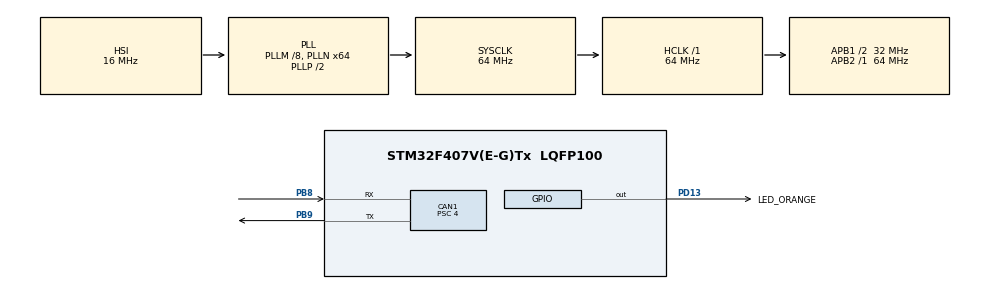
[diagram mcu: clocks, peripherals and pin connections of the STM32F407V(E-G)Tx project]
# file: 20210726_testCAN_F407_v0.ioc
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CAN1.ABOM=ENABLE
CAN1.BS1=CAN_BS1_13TQ
CAN1.BS2=CAN_BS2_2TQ
CAN1.CalculateTimeQuantum=125.0
CAN1.NART=ENABLE
CAN1.Prescaler=4
CAN1.TXFP=ENABLE
Mcu.Family=STM32F4
Mcu.Name=STM32F407V(E-G)Tx
Mcu.Package=LQFP100
NVIC.CAN1_RX0_IRQn=true\:0\:0\:false\:false\:true\:true\:true
NVIC.CAN1_SCE_IRQn=true\:0\:0\:false\:false\:true\:true\:true
NVIC.PriorityGroup=NVIC_PRIORITYGROUP_4
PA13.Mode=Serial_Wire
PA13.Signal=SYS_JTMS-SWDIO
PA14.Mode=Serial_Wire
PA14.Signal=SYS_JTCK-SWCLK
PB8.Mode=Master
PB8.Signal=CAN1_RX
PB9.Mode=Master
PB9.Signal=CAN1_TX
PD13.GPIO_Label=LED_ORANGE
PD13.Signal=GPIO_Output
PH0-OSC_IN.Mode=HSE-External-Oscillator
PH0-OSC_IN.Signal=RCC_OSC_IN
PH1-OSC_OUT.Mode=HSE-External-Oscillator
PH1-OSC_OUT.Signal=RCC_OSC_OUT
ProjectManager.HeapSize=0x200
ProjectManager.StackSize=0x400
ProjectManager.TargetToolchain=STM32CubeIDE
RCC.48MHZClocksFreq_Value=32000000
RCC.AHBFreq_Value=64000000
RCC.APB1CLKDivider=RCC_HCLK_DIV2
RCC.APB1Freq_Value=32000000
RCC.APB1TimFreq_Value=64000000
RCC.APB2Freq_Value=64000000
RCC.APB2TimFreq_Value=64000000
RCC.CortexFreq_Value=64000000
RCC.HCLKFreq_Value=64000000
RCC.HSE_VALUE=8000000
RCC.HSI_VALUE=16000000
RCC.LSE_VALUE=32768
RCC.PLLM=8
RCC.PLLN=64
RCC.SYSCLKFreq_VALUE=64000000
RCC.SYSCLKSource=RCC_SYSCLKSOURCE_PLLCLK
RCC.VCOOutputFreq_Value=128000000
board=custom

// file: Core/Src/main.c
/* USER CODE BEGIN Header */
/**
  ******************************************************************************
  * @file           : main.c
  * @brief          : Main program body
  ******************************************************************************
  * @attention
  *
  * <h2><center>&copy; Copyright (c) 2021 STMicroelectronics.
  * All rights reserved.</center></h2>
  *
  * This software component is licensed by ST under BSD 3-Clause license,
  * the "License"; You may not use this file except in compliance with the
  * License. You may obtain a copy of the License at:
  *                        opensource.org/licenses/BSD-3-Clause
  *
  ******************************************************************************
  */
/* USER CODE END Header */

#include "main.h"

CAN_HandleTypeDef hcan1;

/* USER CODE BEGIN PV */
CAN_TxHeaderTypeDef TxHeader;
CAN_RxHeaderTypeDef RxHeader;
uint8_t TxData[8] = {0,};
uint8_t RxData[8] = {0,};
uint32_t TxMailbox = 0;
/* USER CODE END PV */

void SystemClock_Config(void);
static void MX_GPIO_Init(void);
static void MX_CAN1_Init(void);

/* USER CODE BEGIN 0 */
void HAL_CAN_RxFifo0MsgPendingCallback(CAN_HandleTypeDef *hcan)
{
    if(HAL_CAN_GetRxMessage(hcan, CAN_RX_FIFO0, &RxHeader, RxData) == HAL_OK)
    {
        HAL_GPIO_TogglePin(LED_ORANGE_GPIO_Port, LED_ORANGE_Pin);
    }
}

void HAL_CAN_ErrorCallback(CAN_HandleTypeDef *hcan)
{
//    uint32_t er = HAL_CAN_GetError(hcan);
//    sprintf(trans_str,"ER CAN %lu %08lX", er, er);
//    HAL_UART_Transmit(&huart1, (uint8_t*)trans_str, strlen(trans_str), 100);
}
/* USER CODE END 0 */

int main(void)
{

  /* MCU Configuration--------------------------------------------------------*/

  /* Reset of all peripherals, Initializes the Flash interface and the Systick. */
  HAL_Init();

  /* Configure the system clock */
  SystemClock_Config();

  /* Initialize all configured peripherals */
  MX_GPIO_Init();
  MX_CAN1_Init();
  /* USER CODE BEGIN 2 */
  TxHeader.StdId = 0x0378;
  TxHeader.ExtId = 0;
  TxHeader.RTR = CAN_RTR_DATA; //CAN_RTR_REMOTE
  TxHeader.IDE = CAN_ID_STD;   // CAN_ID_EXT
  TxHeader.DLC = 8;
  TxHeader.TransmitGlobalTime = 0;

  for(uint8_t i = 0; i < 8; i++)
  {
      TxData[i] = (i + 10);
  }

  HAL_CAN_Start(&hcan1);

  HAL_CAN_ActivateNotification(&hcan1, CAN_IT_RX_FIFO0_MSG_PENDING | CAN_IT_ERROR | CAN_IT_BUSOFF | CAN_IT_LAST_ERROR_CODE);
  /* USER CODE END 2 */

  /* Infinite loop */
  /* USER CODE BEGIN WHILE */
  while (1)
  {
	  while(HAL_CAN_GetTxMailboxesFreeLevel(&hcan1) == 0);

    /* USER CODE END WHILE */

  }
}

void SystemClock_Config(void)
{
  RCC_OscInitTypeDef RCC_OscInitStruct = {0};
  RCC_ClkInitTypeDef RCC_ClkInitStruct = {0};

  /** Configure the main internal regulator output voltage
  */
  __HAL_RCC_PWR_CLK_ENABLE();
  __HAL_PWR_VOLTAGESCALING_CONFIG(PWR_REGULATOR_VOLTAGE_SCALE1);
  /** Initializes the CPU, AHB and APB busses clocks
  */
  RCC_OscInitStruct.OscillatorType = RCC_OSCILLATORTYPE_HSI;
  RCC_OscInitStruct.HSIState = RCC_HSI_ON;
  RCC_OscInitStruct.HSICalibrationValue = RCC_HSICALIBRATION_DEFAULT;
  RCC_OscInitStruct.PLL.PLLState = RCC_PLL_ON;
  RCC_OscInitStruct.PLL.PLLSource = RCC_PLLSOURCE_HSI;
  RCC_OscInitStruct.PLL.PLLM = 8;
  RCC_OscInitStruct.PLL.PLLN = 64;
  RCC_OscInitStruct.PLL.PLLP = RCC_PLLP_DIV2;
  RCC_OscInitStruct.PLL.PLLQ = 4;
  if (HAL_RCC_OscConfig(&RCC_OscInitStruct) != HAL_OK)
  {
    Error_Handler();
  }
  /** Initializes the CPU, AHB and APB busses clocks
  */
  RCC_ClkInitStruct.ClockType = RCC_CLOCKTYPE_HCLK|RCC_CLOCKTYPE_SYSCLK
                              |RCC_CLOCKTYPE_PCLK1|RCC_CLOCKTYPE_PCLK2;
  RCC_ClkInitStruct.SYSCLKSource = RCC_SYSCLKSOURCE_PLLCLK;
  RCC_ClkInitStruct.AHBCLKDivider = RCC_SYSCLK_DIV1;
  RCC_ClkInitStruct.APB1CLKDivider = RCC_HCLK_DIV2;
  RCC_ClkInitStruct.APB2CLKDivider = RCC_HCLK_DIV1;

  if (HAL_RCC_ClockConfig(&RCC_ClkInitStruct, FLASH_LATENCY_2) != HAL_OK)
  {
    Error_Handler();
  }
}

static void MX_CAN1_Init(void)
{

  /* USER CODE BEGIN CAN1_Init 0 */
	CAN_FilterTypeDef  sFilterConfig;
  /* USER CODE END CAN1_Init 0 */

  hcan1.Instance = CAN1;
  hcan1.Init.Prescaler = 4;
  hcan1.Init.Mode = CAN_MODE_NORMAL;
  hcan1.Init.SyncJumpWidth = CAN_SJW_1TQ;
  hcan1.Init.TimeSeg1 = CAN_BS1_13TQ;
  hcan1.Init.TimeSeg2 = CAN_BS2_2TQ;
  hcan1.Init.TimeTriggeredMode = DISABLE;
  hcan1.Init.AutoBusOff = ENABLE;
  hcan1.Init.AutoWakeUp = DISABLE;
  hcan1.Init.AutoRetransmission = ENABLE;
  hcan1.Init.ReceiveFifoLocked = DISABLE;
  hcan1.Init.TransmitFifoPriority = ENABLE;
  if (HAL_CAN_Init(&hcan1) != HAL_OK)
  {
    Error_Handler();
  }
  /* USER CODE BEGIN CAN1_Init 2 */
  sFilterConfig.FilterBank = 0;
  sFilterConfig.FilterMode = CAN_FILTERMODE_IDMASK;
  sFilterConfig.FilterScale = CAN_FILTERSCALE_32BIT;
  sFilterConfig.FilterIdHigh = 0x0000;
  sFilterConfig.FilterIdLow = 0x0000;
  sFilterConfig.FilterMaskIdHigh = 0x0000;
  sFilterConfig.FilterMaskIdLow = 0x0000;
  sFilterConfig.FilterFIFOAssignment = CAN_RX_FIFO0;
  sFilterConfig.FilterActivation = ENABLE;
  //sFilterConfig.SlaveStartFilterBank = 14;

  if(HAL_CAN_ConfigFilter(&hcan1, &sFilterConfig) != HAL_OK)
  {
  Error_Handler();
  }
  /* USER CODE END CAN1_Init 2 */

}

static void MX_GPIO_Init(void)
{
  GPIO_InitTypeDef GPIO_InitStruct = {0};

  /* GPIO Ports Clock Enable */
  __HAL_RCC_GPIOH_CLK_ENABLE();
  __HAL_RCC_GPIOD_CLK_ENABLE();
  __HAL_RCC_GPIOA_CLK_ENABLE();
  __HAL_RCC_GPIOB_CLK_ENABLE();

  /*Configure GPIO pin Output Level */
  HAL_GPIO_WritePin(LED_ORANGE_GPIO_Port, LED_ORANGE_Pin, GPIO_PIN_RESET);

  /*Configure GPIO pin : LED_ORANGE_Pin */
  GPIO_InitStruct.Pin = LED_ORANGE_Pin;
  GPIO_InitStruct.Mode = GPIO_MODE_OUTPUT_PP;
  GPIO_InitStruct.Pull = GPIO_NOPULL;
  GPIO_InitStruct.Speed = GPIO_SPEED_FREQ_LOW;
  HAL_GPIO_Init(LED_ORANGE_GPIO_Port, &GPIO_InitStruct);

}

void Error_Handler(void)
{
}

/************************ (C) COPYRIGHT STMicroelectronics *****END OF FILE****/
